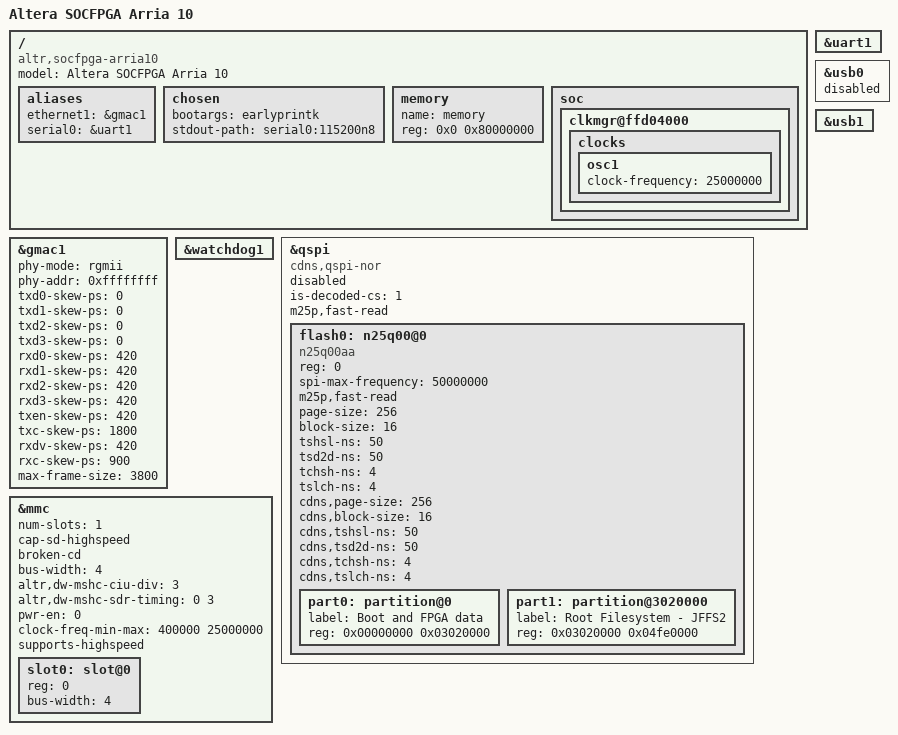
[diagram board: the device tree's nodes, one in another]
/*
 * Copyright (C) 2015 Altera Corporation. All rights reserved.
 *
 * This program is free software; you can redistribute it and/or modify
 * it under the terms and conditions of the GNU General Public License,
 * version 2, as published by the Free Software Foundation.
 *
 * This program is distributed in the hope it will be useful, but WITHOUT
 * ANY WARRANTY; without even the implied warranty of MERCHANTABILITY or
 * FITNESS FOR A PARTICULAR PURPOSE.  See the GNU General Public License for
 * more details.
 *
 * You should have received a copy of the GNU General Public License along with
 * this program.  If not, see <http://www.gnu.org/licenses/>.
 */

#include "socfpga_arria10.dtsi"

/ {
	model = "Altera SOCFPGA Arria 10";
	compatible = "altr,socfpga-arria10", "altr,socfpga";

	aliases {
		ethernet1 = &gmac1;
		serial0 = &uart1;
	};

	chosen {
		bootargs = "earlyprintk";
		stdout-path = "serial0:115200n8";
	};

	memory {
		name = "memory";
		device_type = "memory";
		reg = <0x0 0x80000000>; /* 2GB */
	};

	soc {
		clkmgr@ffd04000 {
			clocks {
				osc1 {
					clock-frequency = <25000000>;
				};
			};
		};
	};
};

&gmac1 {
	phy-mode = "rgmii";
	phy-addr = <0xffffffff>; /* probe for phy addr */

	/*
	 * These skews assume the user's FPGA design is adding 600ps of delay
	 * for TX_CLK on Arria 10.
	 *
	 * All skews are offset since hardware skew values for the ksz9031
	 * range from a negative skew to a positive skew.
	 * See the micrel-ksz90x1.txt Documentation file for details.
	 */
	txd0-skew-ps = <0>; /* -420ps */
	txd1-skew-ps = <0>; /* -420ps */
	txd2-skew-ps = <0>; /* -420ps */
	txd3-skew-ps = <0>; /* -420ps */
	rxd0-skew-ps = <420>; /* 0ps */
	rxd1-skew-ps = <420>; /* 0ps */
	rxd2-skew-ps = <420>; /* 0ps */
	rxd3-skew-ps = <420>; /* 0ps */
	txen-skew-ps = <420>; /* 0ps */
	txc-skew-ps = <1800>; /* 900ps */
	rxdv-skew-ps = <420>; /* 0ps */
	rxc-skew-ps = <900>; /* 0ps */
	max-frame-size = <3800>;
	status = "okay";
};

&uart1 {
	status = "okay";
};

&usb0 {
	status = "disabled";
};

&usb1 {
	status = "okay";
};

&watchdog1 {
	status = "okay";
};

&qspi {
	status = "disabled";

	compatible = "cdns,qspi-nor";
	is-decoded-cs = <1>;
	m25p,fast-read;

	flash0: n25q00@0 {
		#address-cells = <1>;   /* appended from boardinfo */
		#size-cells = <1>;      /* appended from boardinfo */
		compatible = "n25q00aa";        /* appended from boardinfo */
		reg = <0>;      /* appended from boardinfo */
		spi-max-frequency = <50000000>; /* appended from boardinfo */
		m25p,fast-read; /* appended from boardinfo */
		page-size = <256>;      /* appended from boardinfo */
		block-size = <16>;      /* appended from boardinfo */
		tshsl-ns = <50>;        /* appended from boardinfo */
		tsd2d-ns = <50>;        /* appended from boardinfo */
		tchsh-ns = <4>; /* appended from boardinfo */
		tslch-ns = <4>; /* appended from boardinfo */
		cdns,page-size = <256>; /* appended from boardinfo */
		cdns,block-size = <16>; /* appended from boardinfo */
		cdns,tshsl-ns = <50>;   /* appended from boardinfo */
		cdns,tsd2d-ns = <50>;   /* appended from boardinfo */
		cdns,tchsh-ns = <4>;    /* appended from boardinfo */
		cdns,tslch-ns = <4>;    /* appended from boardinfo */
		
		part0: partition@0 {
			label = "Boot and FPGA data";   /* appended from boardinfo */
			reg = <0x00000000 0x03020000>;  /* appended from boardinfo */
		}; //end partition@0 (part0)
		
		part1: partition@3020000 {
			label = "Root Filesystem - JFFS2";      /* appended from boardinfo */
			reg = <0x03020000 0x04fe0000>;  /* appended from boardinfo */
		}; //end partition@3020000 (part1)
	}; //end n25q00@0 (flash0)	
};

&mmc {
	status = "okay";
	num-slots = <1>;
	cap-sd-highspeed;
	broken-cd;
	bus-width = <4>;
	altr,dw-mshc-ciu-div = <3>;
	altr,dw-mshc-sdr-timing = <0 3>;
	pwr-en = <0>;
	
	clock-freq-min-max = <400000 25000000>;
	supports-highspeed;
	
	slot0: slot@0 {
		reg = <0>;
		bus-width = <4>;
	};	
};
